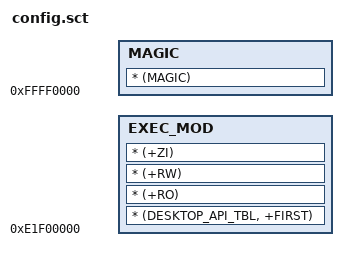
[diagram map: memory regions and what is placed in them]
;/*
;********************************************************************************************************
;*											        ePDK
;*						            the Easy Portable/Player Develop Kits
;*									           hello world sample
;*
;*						        (c) Copyright 2006-2007, Steven.ZGJ China
;*											All	Rights Reserved
;*
;* File    : scatter.sct
;* By      : Steven.ZGJ
;* Version : V1.00
;********************************************************************************************************
;*/

LO_FIRST 0xe1f00000 0x100000
{
    EXEC_MOD 0xe1f00000
    {
        * (DESKTOP_API_TBL, +FIRST)
        * (+RO)
        * (+RW)
        * (+ZI)
	}
    MAGIC  0xFFFF0000
    {
        * (MAGIC)
    }
}


